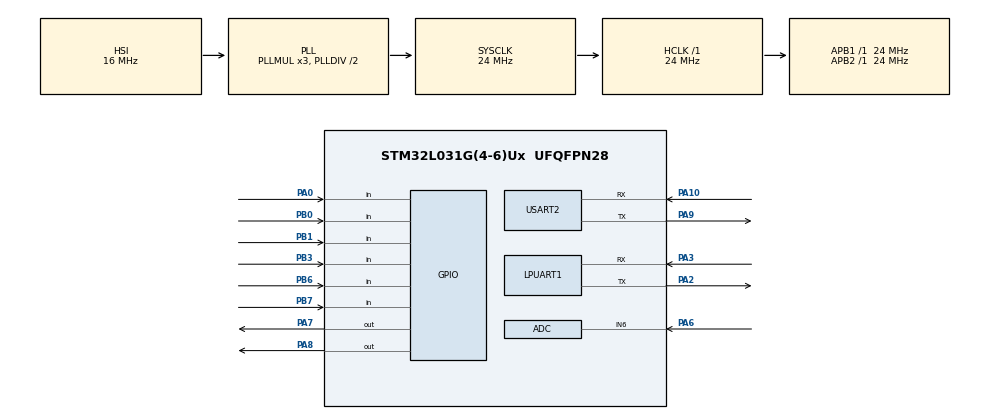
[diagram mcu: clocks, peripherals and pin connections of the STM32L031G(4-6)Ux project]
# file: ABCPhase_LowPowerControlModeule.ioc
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Dma.LPUART1_RX.0.Direction=DMA_PERIPH_TO_MEMORY
Dma.LPUART1_RX.0.Instance=DMA1_Channel3
Dma.LPUART1_RX.0.MemDataAlignment=DMA_MDATAALIGN_BYTE
Dma.LPUART1_RX.0.MemInc=DMA_MINC_ENABLE
Dma.LPUART1_RX.0.Mode=DMA_NORMAL
Dma.LPUART1_RX.0.PeriphDataAlignment=DMA_PDATAALIGN_BYTE
Dma.LPUART1_RX.0.PeriphInc=DMA_PINC_DISABLE
Dma.LPUART1_RX.0.Priority=DMA_PRIORITY_MEDIUM
Dma.LPUART1_TX.1.Direction=DMA_MEMORY_TO_PERIPH
Dma.LPUART1_TX.1.Instance=DMA1_Channel2
Dma.LPUART1_TX.1.MemDataAlignment=DMA_MDATAALIGN_BYTE
Dma.LPUART1_TX.1.MemInc=DMA_MINC_ENABLE
Dma.LPUART1_TX.1.Mode=DMA_NORMAL
Dma.LPUART1_TX.1.PeriphDataAlignment=DMA_PDATAALIGN_BYTE
Dma.LPUART1_TX.1.PeriphInc=DMA_PINC_DISABLE
Dma.LPUART1_TX.1.Priority=DMA_PRIORITY_MEDIUM
Dma.Request0=LPUART1_RX
Dma.Request1=LPUART1_TX
Dma.Request2=USART2_RX
Dma.Request3=USART2_TX
Dma.USART2_RX.2.Direction=DMA_PERIPH_TO_MEMORY
Dma.USART2_RX.2.Instance=DMA1_Channel5
Dma.USART2_RX.2.MemDataAlignment=DMA_MDATAALIGN_BYTE
Dma.USART2_RX.2.MemInc=DMA_MINC_ENABLE
Dma.USART2_RX.2.Mode=DMA_NORMAL
Dma.USART2_RX.2.PeriphDataAlignment=DMA_PDATAALIGN_BYTE
Dma.USART2_RX.2.PeriphInc=DMA_PINC_DISABLE
Dma.USART2_RX.2.Priority=DMA_PRIORITY_LOW
Dma.USART2_TX.3.Direction=DMA_MEMORY_TO_PERIPH
Dma.USART2_TX.3.Instance=DMA1_Channel4
Dma.USART2_TX.3.MemDataAlignment=DMA_MDATAALIGN_BYTE
Dma.USART2_TX.3.MemInc=DMA_MINC_ENABLE
Dma.USART2_TX.3.Mode=DMA_NORMAL
Dma.USART2_TX.3.PeriphDataAlignment=DMA_PDATAALIGN_BYTE
Dma.USART2_TX.3.PeriphInc=DMA_PINC_DISABLE
Dma.USART2_TX.3.Priority=DMA_PRIORITY_LOW
IWDG.Prescaler=IWDG_PRESCALER_64
LPUART1.WordLength=UART_WORDLENGTH_8B
Mcu.Family=STM32L0
Mcu.Name=STM32L031G(4-6)Ux
Mcu.Package=UFQFPN28
NVIC.DMA1_Channel2_3_IRQn=true\:0\:0\:false\:false\:true\:false\:true\:true
NVIC.DMA1_Channel4_5_6_7_IRQn=true\:0\:0\:false\:false\:true\:false\:true\:true
NVIC.LPUART1_IRQn=true\:0\:0\:false\:false\:true\:true\:true\:true
NVIC.USART2_IRQn=true\:0\:0\:false\:false\:true\:true\:true\:true
PA0-CK_IN.Signal=GPIO_Input
PA10.Mode=Asynchronous
PA10.Signal=USART2_RX
PA13.Mode=Serial_Wire
PA13.Signal=SYS_SWDIO
PA14.Mode=Serial_Wire
PA14.Signal=SYS_SWCLK
PA2.Mode=Asynchronous
PA2.Signal=LPUART1_TX
PA3.Mode=Asynchronous
PA3.Signal=LPUART1_RX
PA6.Mode=IN6
PA6.Signal=ADC_IN6
PA7.Signal=GPIO_Output
PA8.Signal=GPIO_Output
PA9.Mode=Asynchronous
PA9.Signal=USART2_TX
PB0.Signal=GPIO_Input
PB1.Signal=GPIO_Input
PB3.Signal=GPIO_Input
PB6.Signal=GPIO_Input
PB7.Signal=GPIO_Input
ProjectManager.HeapSize=0x200
ProjectManager.StackSize=0x400
ProjectManager.TargetToolchain=CMake
RCC.ADCFreq_Value=16000000
RCC.AHBFreq_Value=24000000
RCC.APB1Freq_Value=24000000
RCC.APB1TimFreq_Value=24000000
RCC.APB2Freq_Value=24000000
RCC.APB2TimFreq_Value=24000000
RCC.HCLKFreq_Value=24000000
RCC.HSE_VALUE=8000000
RCC.HSI16_VALUE=16000000
RCC.HSI_VALUE=16000000
RCC.LSE_VALUE=32768
RCC.MSI_VALUE=2097000
RCC.SYSCLKFreq_VALUE=24000000
RCC.SYSCLKSource=RCC_SYSCLKSOURCE_PLLCLK
RCC.VCOOutputFreq_Value=48000000
USART2.VirtualMode-Asynchronous=VM_ASYNC
VP_IWDG_VS_IWDG.Mode=IWDG_Activate
VP_SYS_VS_LPOM.Mode=PowerOptimisation
board=custom

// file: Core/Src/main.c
/* USER CODE BEGIN Header */
/**
  ******************************************************************************
  * @file           : main.c
  * @brief          : Main program body
  ******************************************************************************
  * @attention
  *
  * Copyright (c) 2026 STMicroelectronics.
  * All rights reserved.
  *
  * This software is licensed under terms that can be found in the LICENSE file
  * in the root directory of this software component.
  * If no LICENSE file comes with this software, it is provided AS-IS.
  *
  ******************************************************************************
  */
/* USER CODE END Header */
#include "main.h"
#include "adc.h"
#include "dma.h"
#include "iwdg.h"
#include "usart.h"
#include "gpio.h"

/* USER CODE BEGIN Includes */
#include "app_main.h"
/* USER CODE END Includes */

void SystemClock_Config(void);

int main(void)
{

  /* MCU Configuration--------------------------------------------------------*/

  /* Reset of all peripherals, Initializes the Flash interface and the Systick. */
  HAL_Init();

  /* Configure the system clock */
  SystemClock_Config();

  /* Initialize all configured peripherals */
  MX_GPIO_Init();
  MX_DMA_Init();
  // MX_IWDG_Init();
  MX_LPUART1_UART_Init();
  MX_USART2_UART_Init();
  MX_ADC_Init();
  /* USER CODE BEGIN 2 */
  /* 应用层初始化(Bsp 驱动层在 app_init 内部完成初始化) */
  app_init();
  /* USER CODE END 2 */

  /* Infinite loop */
  while (1)
  {

    /* USER CODE BEGIN 3 */
    app_task();
  }
  /* USER CODE END 3 */
}

void SystemClock_Config(void)
{
  RCC_OscInitTypeDef RCC_OscInitStruct = {0};
  RCC_ClkInitTypeDef RCC_ClkInitStruct = {0};
  RCC_PeriphCLKInitTypeDef PeriphClkInit = {0};

  /** Configure the main internal regulator output voltage
  */
  __HAL_PWR_VOLTAGESCALING_CONFIG(PWR_REGULATOR_VOLTAGE_SCALE1);

  /** Initializes the RCC Oscillators according to the specified parameters
  * in the RCC_OscInitTypeDef structure.
  */
  /* 注意:LSI 已关闭 —— 本工程不再使用 IWDG/LPTIM/RTC(LSI 源),
   * Stop 下不需要任何低频时钟。若日后要重新启用它们,必须在这里
   * 加回 RCC_OSCILLATORTYPE_LSI / RCC_LSI_ON,并在 CubeMX(.ioc) 中同步打开 LSI。 */
  RCC_OscInitStruct.OscillatorType = RCC_OSCILLATORTYPE_HSI;
  RCC_OscInitStruct.HSIState = RCC_HSI_ON;
  RCC_OscInitStruct.HSICalibrationValue = RCC_HSICALIBRATION_DEFAULT;
    RCC_OscInitStruct.PLL.PLLState = RCC_PLL_ON;
  RCC_OscInitStruct.PLL.PLLSource = RCC_PLLSOURCE_HSI;
  RCC_OscInitStruct.PLL.PLLMUL = RCC_PLLMUL_3;
  RCC_OscInitStruct.PLL.PLLDIV = RCC_PLLDIV_2;
  if (HAL_RCC_OscConfig(&RCC_OscInitStruct) != HAL_OK)
  {
    Error_Handler();
  }

  /** Initializes the CPU, AHB and APB buses clocks
  */
  RCC_ClkInitStruct.ClockType = RCC_CLOCKTYPE_HCLK|RCC_CLOCKTYPE_SYSCLK
                              |RCC_CLOCKTYPE_PCLK1|RCC_CLOCKTYPE_PCLK2;
  RCC_ClkInitStruct.SYSCLKSource = RCC_SYSCLKSOURCE_PLLCLK;
  RCC_ClkInitStruct.AHBCLKDivider = RCC_SYSCLK_DIV1;
  RCC_ClkInitStruct.APB1CLKDivider = RCC_HCLK_DIV1;
  RCC_ClkInitStruct.APB2CLKDivider = RCC_HCLK_DIV1;

  if (HAL_RCC_ClockConfig(&RCC_ClkInitStruct, FLASH_LATENCY_1) != HAL_OK)
  {
    Error_Handler();
  }
  PeriphClkInit.PeriphClockSelection = RCC_PERIPHCLK_USART2|RCC_PERIPHCLK_LPUART1;
  PeriphClkInit.Usart2ClockSelection = RCC_USART2CLKSOURCE_PCLK1;
  PeriphClkInit.Lpuart1ClockSelection = RCC_LPUART1CLKSOURCE_PCLK1;
  if (HAL_RCCEx_PeriphCLKConfig(&PeriphClkInit) != HAL_OK)
  {
    Error_Handler();
  }
}

void Error_Handler(void)
{
  __disable_irq();
  while (1)
  {
  }
}
